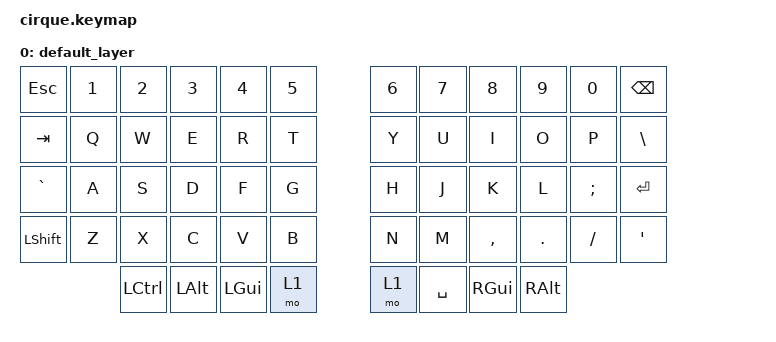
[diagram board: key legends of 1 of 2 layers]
#include <behaviors.dtsi>
#include <dt-bindings/zmk/keys.h>

/ {
        keymap {
                compatible = "zmk,keymap";

                default_layer {
// ---------------------------------------------------------------------------------
// | ESC  |  1  |  2  |  3  |  4  |  5  |     |  6  |  7  |  8  |  9  |  0  | BKSP |
// | TAB  |  Q  |  W  |  E  |  R  |  T  |     |  Y  |  U  |  I  |  O  |  P  |  \   |
// | `    |  A  |  S  |  D  |  F  |  G  |     |  H  |  J  |  K  |  L  |  ;  |  ENT |
// | SHFT |  Z  |  X  |  C  |  V  |  B  |     |  N  |  M  |  ,  |  .  |  /  | APOS |
//              | CTRL| ALT | GUI | LOW |     | LOW | SPC | GUI | ALT |
                        bindings = <
   &kp ESC    &kp N1    &kp N2    &kp N3     &kp N4     &kp N5               &kp N6     &kp N7    &kp N8     &kp N9    &kp N0    &kp BSPC
   &kp TAB    &kp Q     &kp W     &kp E      &kp R      &kp T                &kp Y      &kp U     &kp I      &kp O     &kp P     &kp BSLH
   &kp GRAVE  &kp A     &kp S     &kp D      &kp F      &kp G                &kp H      &kp J     &kp K      &kp L     &kp SEMI  &kp RET
   &kp LSHFT  &kp Z     &kp X     &kp C      &kp V      &kp B                &kp N      &kp M     &kp COMMA  &kp DOT   &kp FSLH  &kp APOS
                        &kp LCTRL &kp LALT   &kp LGUI   &mo 1                &mo 1  &kp SPACE     &kp RGUI   &kp RALT 
                        >;
                };
                lower_layer {
// ------------------------------------------------------------------------------------------------------------
// |       |       |       | BR_DWN| BR_UP |       |          |       |       |       |       |       |       |
// |       |       |       |       |       |       |          |       |       | UARW  |       |       |       |
// |       |       |       | LBKT  | RBKT  |       |          |       | LARW  | DARW  | RARW  |       |       |
// |       |       |       |       |       |       |          |       |   -   |   "   |   =   |       |       |
                        bindings = <
   &trans    &trans         &trans         &kp C_BRI_DN   &kp C_BRI_UP   &trans                &trans    &trans     &trans   &trans     &trans  &trans
   &trans    &trans         &trans         &trans         &trans         &trans                &trans    &trans     &kp UP   &trans     &trans  &trans
   &trans    &trans         &trans         &kp LBKT       &kp RBKT       &trans                &trans    &kp LEFT   &kp DOWN &kp RIGHT  &trans  &trans
   &trans    &trans         &trans         &trans         &trans         &trans                &trans    &kp MINUS  &kp SQT  &kp EQUAL  &trans  &trans
                        >;
                };
        };
};
